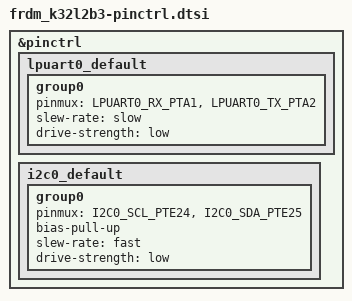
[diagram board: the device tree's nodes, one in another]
/*
 * Copyright (c) 2025 Ishraq Ibne Ashraf <ishraq.i.ashraf@gmail.com>
 *
 * SPDX-License-Identifier: Apache-2.0
 */

#include <nxp/kinetis/K32L2B31VLH0A-pinctrl.h>

&pinctrl {
	lpuart0_default: lpuart0_default {
		group0 {
			pinmux = <LPUART0_RX_PTA1>,
				 <LPUART0_TX_PTA2>;
			slew-rate = "slow";
			drive-strength = "low";
		};
	};

	i2c0_default: i2c0_default {
		group0 {
			pinmux = <I2C0_SCL_PTE24>,
				 <I2C0_SDA_PTE25>;
			bias-pull-up;
			slew-rate = "fast";
			drive-strength = "low";
		};
	};
};
